# CH32V205 register map
Vendor: WCH Ltd.; File version: 1.0
Registers are 32-bit, read-write, reset 0x0 unless marked. A register's access mark holds for its fields unless they carry their own. Offsets are from the block's base; [hi:lo] are bit positions; lines under a group give offsets from that group; {n}, {i} and the like mark numbered series.

## ADC__TKEY — Analog to digital converter_TOUCHKEY detection
Base 0x40012400
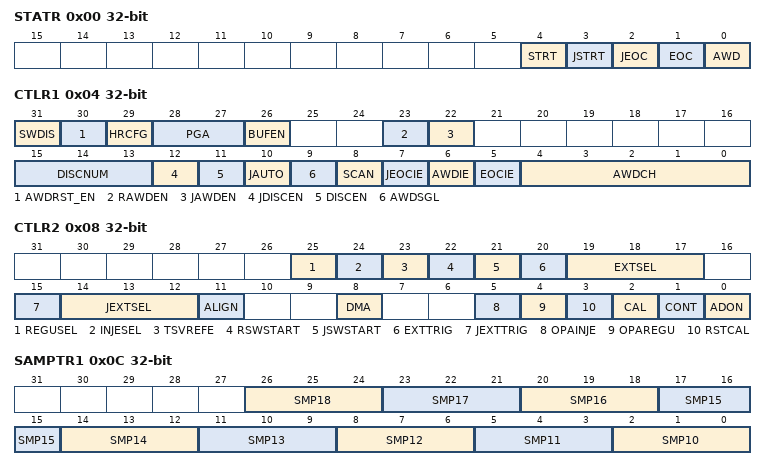
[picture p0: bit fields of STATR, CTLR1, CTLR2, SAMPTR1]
0x00 STATR — status register
  [4] STRT — Regular channel start flag
  [3] JSTRT — Injected channel start flag
  [2] JEOC — Injected channel end of conversion
  [1] EOC — Regular channel end of conversion
  [0] AWD — Analog watchdog flag
0x04 CTLR1 — control register 1
  [31] SWDIS — ADC channel pre-switching function
  [30] AWDRST_EN — simulation watchdog reset enable
  [29] HRCFG — sampling switch resistance configuration
  [28:27] PGA — ADC_PGA
  [26] BUFEN — ADC BUF Enable
  [23] RAWDEN — Analog watchdog enable on regular channels
  [22] JAWDEN — Analog watchdog enable on injected channels
  [15:13] DISCNUM — Discontinuous mode channel count
  [12] JDISCEN — Discontinuous mode on injected channels
  [11] DISCEN — Discontinuous mode on regular channels
  [10] JAUTO — Automatic injected group conversion
  [9] AWDSGL — Enable the watchdog on a single channel in scan mode
  [8] SCAN — Scan mode enable
  [7] JEOCIE — Interrupt enable for injected channels
  [6] AWDIE — Analog watchdog interrupt enable
  [5] EOCIE — Interrupt enable for EOC
  [4:0] AWDCH — Analog watchdog channel select bits
0x08 CTLR2 — control register 2
  [25] REGUSEL — Rule group trigger source selection
  [24] INJESEL — Injection Group Trigger Source Selection
  [23] TSVREFE — Temperature sensor and VREFINT enable
  [22] RSWSTART — Start conversion of regular channels
  [21] JSWSTART — Start conversion of injected channels
  [20] EXTTRIG — External trigger conversion mode for regular channels
  [19:17] EXTSEL — External event select for regular group
  [15] JEXTTRIG — External trigger conversion mode for injected channels
  [14:12] JEXTSEL — External event select for injected group
  [11] ALIGN — Data alignment
  [8] DMA — Direct memory access mode
  [5] OPAINJE — The OPA polling event triggers the ADC injection group conversion function configuration
  [4] OPAREGU — OPA polling event triggers ADC rule group conversion function configuration
  [3] RSTCAL — Reset calibration
  [2] CAL — A/D calibration
  [1] CONT — Continuous conversion
  [0] ADON — A/D converter ON / OFF
0x0C SAMPTR1 — sample time register 1
  [3n-28:3n-30] SMP{n} (n=10..18) — Channel {n} sample time selection
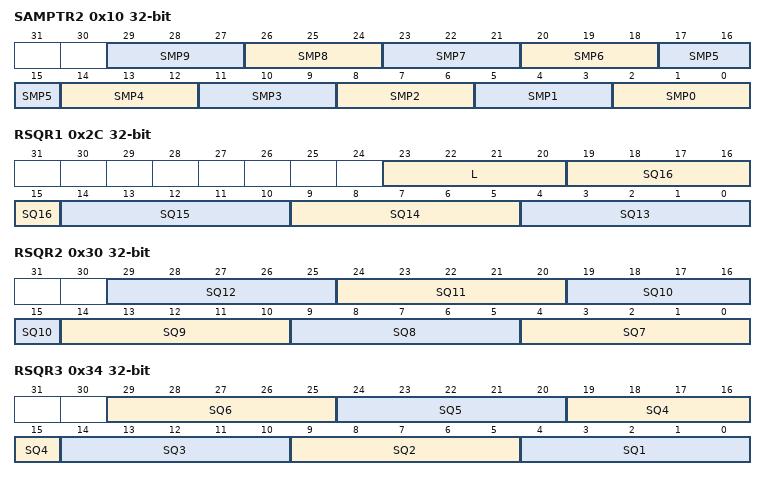
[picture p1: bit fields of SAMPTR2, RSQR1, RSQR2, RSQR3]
0x10 SAMPTR2 — sample time register 2
  [3n+2:3n] SMP{n} (n=0..9) — Channel {n} sample time selection
{0x10+4i} IOFR{i} (i=1..4) — injected channel data offset register x
  [11:0] JOFFSET{i} — Data offset for injected channel x
0x24 WDHTR reset 0xFFF — watchdog higher threshold register
  [11:0] HT — Analog watchdog higher threshold
0x28 WDLTR — watchdog lower threshold register
  [11:0] LT — Analog watchdog lower threshold
0x2C RSQR1 — regular sequence register 1
  [23:20] L — Regular channel sequence length
  [5n-61:5n-65] SQ{n} (n=13..16) — {n}th conversion in regular sequence
0x30 RSQR2 — regular sequence register 2
  [5n-31:5n-35] SQ{n} (n=7..12) — {n}th conversion in regular sequence
0x34 RSQR3 — regular sequence register 3
  [29:25] SQ6 — 6th conversion in regular sequence
  [24:20] SQ5 — 5th conversion in regular sequence
  [19:15] SQ4 — 4th conversion in regular sequence
  [14:10] SQ3 — 3rd conversion in regular sequence
  [9:5] SQ2 — 2nd conversion in regular sequence
  [4:0] SQ1 — 1st conversion in regular sequence
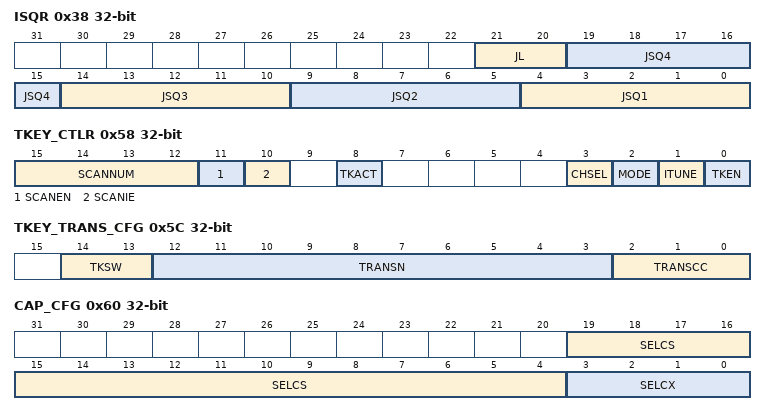
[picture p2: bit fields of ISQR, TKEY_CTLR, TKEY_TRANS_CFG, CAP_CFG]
0x38 ISQR — injected sequence register
  [21:20] JL — Injected sequence length
  [19:15] JSQ4 — 4th conversion in injected sequence
  [14:10] JSQ3 — 3rd conversion in injected sequence
  [9:5] JSQ2 — 2nd conversion in injected sequence
  [4:0] JSQ1 — 1st conversion in injected sequence
0x3C IDATAR1_CHGOFFSET ro — injected data register 1
  [15:0] IDATA — Injected data
{0x38+4i} IDATAR{i} ro (i=2..4) — injected data register {i}
  [15:0] JDATA — Injected data
0x4C RDATAR ro — regular data register
  [15:0] DATA — Regular data
0x58 TKEY_CTLR — TKEY control register
  [15:12] SCANNUM — Configure the number of TKEY scanning channels
  [11] SCANEN — TKEY channel sweep function enable
  [10] SCANIE — TKEY Channel Scan Interrupt Enable
  [8] TKACT — TKEY triggers the control
  [3] CHSEL — Channel selection
  [2] MODE — TKEY mode configuration
  [1] ITUNE — Charging current configuration of the TKEY module
  [0] TKEN — TKEY enabler
0x5C TKEY_TRANS_CFG — Charge Shift Configuration Register
  [14:13] TKSW — TKEY switch switching time configuration
  [12:3] TRANSN — The actual number of transfer cycles is TRANSN+1, that is, the maximum number of transfer cycles is 1024
  [2:0] TRANSCC — In charge transfer mode, touch the button capacitor charge charge T2 and charge transfer time T4 configuration bits
0x60 CAP_CFG — Capacitor Configuration Register
  [19:4] SELCS — In charge transfer mode, a channel for charge transfer is configured
  [3:0] SELCX — In charge transfer mode, the channel with an external reference capacitor is configured, and in current source charging mode, this bit is invalid
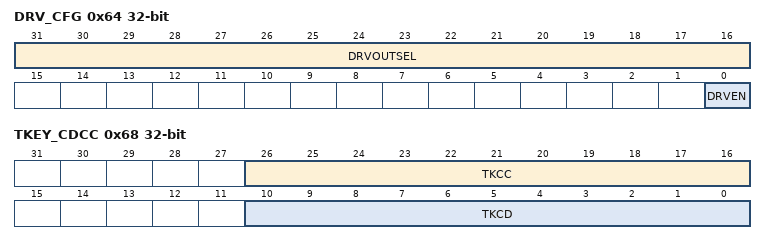
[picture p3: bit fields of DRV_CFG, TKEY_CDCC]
0x64 DRV_CFG — Driver Shield Configuration Register
  [31:16] DRVOUTSEL — Drive shield channel selection, active high
  [0] DRVEN — Drive Shielding Function Enable Position
0x68 TKEY_CDCC — TKEY Charge-Discharge Configuration Register
  [26:16] TKCC — In the current source charging mode, the charging time is configured
  [10:0] TKCD — In current source charging mode, the discharge time is configured
0x6C TKEY_SR — TKEY Status Register
  [0] SCANIF — The TKEY channel scan is interrupted at the end of the mark, the software writes 0 clear, and the write 1 is invalid
